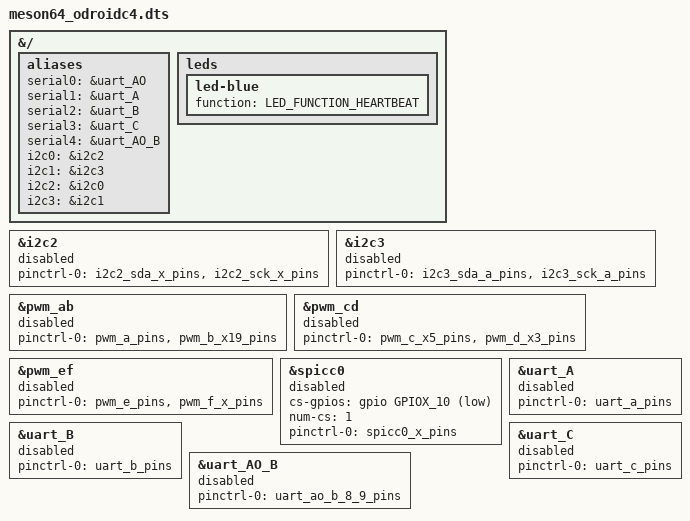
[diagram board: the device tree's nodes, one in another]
// SPDX-License-Identifier: (GPL-2.0+ OR MIT)
/*
 * Copyright (c) 2026 Hardkernel Co., Ltd.
 *
 */

#include "meson-sm1-odroid-c4.dts"
#include <dt-bindings/leds/common.h>

&{/} {
	aliases {
		serial0 = &uart_AO;
		serial1 = &uart_A;
		serial2 = &uart_B;
		serial3 = &uart_C;
		serial4 = &uart_AO_B;
		i2c0 = &i2c2;
		i2c1 = &i2c3;
		i2c2 = &i2c0;
		i2c3 = &i2c1;
	};

	leds {
		led-blue {
			function = LED_FUNCTION_HEARTBEAT;
		};
	};
};

&i2c2 {
	status = "disabled";
	pinctrl-0 = <&i2c2_sda_x_pins>, <&i2c2_sck_x_pins>;
	pinctrl-names = "default";
};

&i2c3 {
	status = "disabled";
	pinctrl-0 = <&i2c3_sda_a_pins>, <&i2c3_sck_a_pins>;
	pinctrl-names = "default";
};

&pwm_ab {
	status = "disabled";
	pinctrl-names = "default";
	pinctrl-0 = <&pwm_a_pins &pwm_b_x19_pins>;
};

&pwm_cd {
	status = "disabled";
	pinctrl-names = "default";
	pinctrl-0 = <&pwm_c_x5_pins &pwm_d_x3_pins>;
};

&pwm_ef {
	status = "disabled";
	pinctrl-names = "default";
	pinctrl-0 = <&pwm_e_pins &pwm_f_x_pins>;
};

&spicc0 {
	status = "disabled";
	cs-gpios = <&gpio GPIOX_10 GPIO_ACTIVE_LOW>;
	num-cs = <1>;
	pinctrl-0 = <&spicc0_x_pins>;
	pinctrl-names = "default";
};

&uart_A {
	status = "disabled";
	pinctrl-0 = <&uart_a_pins>;
	pinctrl-names = "default";
};

&uart_B {
	status = "disabled";
	pinctrl-0 = <&uart_b_pins>;
	pinctrl-names = "default";
};

&uart_C {
	status = "disabled";
	pinctrl-0 = <&uart_c_pins>;
	pinctrl-names = "default";
};

&uart_AO_B {
	status = "disabled";
	pinctrl-0 = <&uart_ao_b_8_9_pins>;
	pinctrl-names = "default";
};
